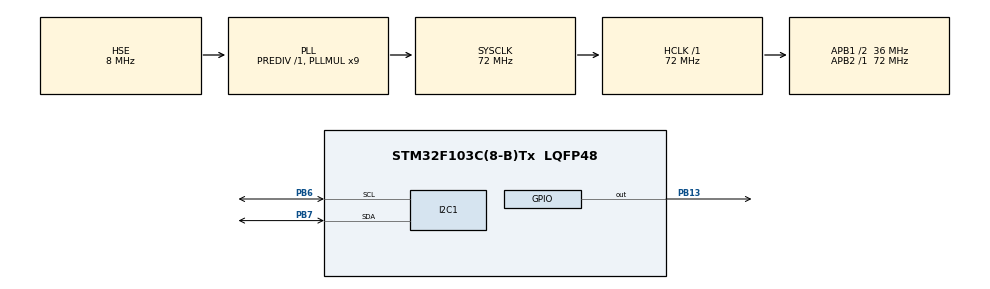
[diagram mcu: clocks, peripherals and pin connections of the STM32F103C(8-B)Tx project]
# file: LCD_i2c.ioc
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Mcu.Family=STM32F1
Mcu.Name=STM32F103C(8-B)Tx
Mcu.Package=LQFP48
NVIC.I2C1_ER_IRQn=true\:1\:0\:true\:false\:true\:true\:true\:true
NVIC.I2C1_EV_IRQn=true\:1\:0\:true\:false\:true\:true\:true\:true
NVIC.PriorityGroup=NVIC_PRIORITYGROUP_4
NVIC.TIM2_IRQn=true\:1\:0\:true\:false\:true\:true\:true\:true
PA13.Mode=Serial_Wire
PA13.Signal=SYS_JTMS-SWDIO
PA14.Mode=Serial_Wire
PA14.Signal=SYS_JTCK-SWCLK
PB13.Signal=GPIO_Output
PB6.Mode=I2C
PB6.Signal=I2C1_SCL
PB7.Mode=I2C
PB7.Signal=I2C1_SDA
PD0-OSC_IN.Mode=HSE-External-Oscillator
PD0-OSC_IN.Signal=RCC_OSC_IN
PD1-OSC_OUT.Mode=HSE-External-Oscillator
PD1-OSC_OUT.Signal=RCC_OSC_OUT
ProjectManager.HeapSize=0x200
ProjectManager.StackSize=0x400
ProjectManager.TargetToolchain=STM32CubeIDE
RCC.AHBFreq_Value=72000000
RCC.APB1CLKDivider=RCC_HCLK_DIV2
RCC.APB1Freq_Value=36000000
RCC.APB1TimFreq_Value=72000000
RCC.APB2Freq_Value=72000000
RCC.APB2TimFreq_Value=72000000
RCC.HCLKFreq_Value=72000000
RCC.PLLMUL=RCC_PLL_MUL9
RCC.PLLSourceVirtual=RCC_PLLSOURCE_HSE
RCC.SYSCLKFreq_VALUE=72000000
RCC.SYSCLKSource=RCC_SYSCLKSOURCE_PLLCLK
RCC.USBFreq_Value=72000000
TIM2.Period=65534
TIM2.Prescaler=71
VP_TIM2_VS_ClockSourceINT.Mode=Internal
board=custom

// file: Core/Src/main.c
/* USER CODE BEGIN Header */
/**
  ******************************************************************************
  * @file           : main.c
  * @brief          : Main program body
  ******************************************************************************
  * @attention
  *
  * Copyright (c) 2023 STMicroelectronics.
  * All rights reserved.
  *
  * This software is licensed under terms that can be found in the LICENSE file
  * in the root directory of this software component.
  * If no LICENSE file comes with this software, it is provided AS-IS.
  *
  ******************************************************************************
  */
/* USER CODE END Header */
#include "main.h"

/* USER CODE BEGIN Includes */
#include "i2c-lcd.h"
#include "stdio.h"
/* USER CODE END Includes */

/* USER CODE BEGIN PD */
#define DHT11_GPIO_Port GPIOB
#define DHT11_Pin GPIO_PIN_13
/* USER CODE END PD */

I2C_HandleTypeDef hi2c1;

TIM_HandleTypeDef htim2;
float t=0,h=0;

void SystemClock_Config(void);
static void MX_GPIO_Init(void);
static void MX_I2C1_Init(void);
static void MX_TIM2_Init(void);

/* USER CODE BEGIN 0 */
// delay theo mirco giây
void delay_us(int us){
	 __HAL_TIM_SetCounter(&htim2, 0);
	 while (__HAL_TIM_GetCounter(&htim2) < us);
}

// delay theo mili giây
void delay_ms(int ms){
	for(int i =0; i < ms; i++){
			delay_us(1000);
	}
}
/*----------DHT11-----------*/
void DHT_SetPinOut()
{
	GPIO_InitTypeDef GPIO_InitStruct = {0};
	GPIO_InitStruct.Pin = DHT11_Pin;
  GPIO_InitStruct.Mode = GPIO_MODE_OUTPUT_PP;
  GPIO_InitStruct.Speed = GPIO_SPEED_FREQ_LOW;
  HAL_GPIO_Init(DHT11_GPIO_Port, &GPIO_InitStruct);
}
void DHT_SetPinIn()
{
	GPIO_InitTypeDef GPIO_InitStruct = {0};
	GPIO_InitStruct.Pin = DHT11_Pin;
  GPIO_InitStruct.Mode = GPIO_MODE_INPUT;
  GPIO_InitStruct.Pull = GPIO_NOPULL;
  HAL_GPIO_Init(DHT11_GPIO_Port, &GPIO_InitStruct);
}

void DHT_WritePin(uint8_t Value)
{
	HAL_GPIO_WritePin(DHT11_GPIO_Port, DHT11_Pin, Value);
}
static uint8_t DHT_ReadPin()
{
	uint8_t Value;
	Value =  HAL_GPIO_ReadPin(DHT11_GPIO_Port, DHT11_Pin);
	return Value;
}

uint8_t DHT_Start()
{
	uint8_t Response = 0;
	DHT_SetPinOut();
	DHT_WritePin(0);
	delay_us(18000);
	DHT_SetPinIn();
	//delay_us(50);
	while(DHT_ReadPin());
	Response = DHT_ReadPin();
//	if (!DHT_ReadPin())
//	{
//		delay_us(80);
//		if(DHT_ReadPin())
//		{
//			Response = 1;
//		}
//		else
//		{
//			Response = 0;
//		}
//	}
//	while(DHT_ReadPin());
	return Response;
}
uint8_t DHT_Read()
{
	uint8_t Value = 0;
	for(int i = 0; i<8; i++)
	{
		while(!DHT_ReadPin());
		delay_us(40);
		if(!DHT_ReadPin())
		{
			Value &= ~(1<<(7-i));
		}
		else Value |= 1<<(7-i);
		while(DHT_ReadPin());
	}
	return Value;
}

//************************** High Level Layer ********************************************************//

void DHT_ReadTempHum()
{
	uint8_t Respone = 0;
	uint8_t Temp1, RH1;
//	uint16_t Temp, Humi, SUM = 0;
	Respone = DHT_Start();
	if(Respone){
		RH1 = DHT_Read();
		//RH2 = DHT_Read();
		Temp1 = DHT_Read();
		//Temp2 = DHT_Read();
	//	SUM = DHT_Read();
	//	Temp = (Temp1<<8)|Temp2;
	//	Humi = (RH1<<8)|RH2;
		t = (float)(Temp1);
		h = (float)(RH1);
	}
	else{
		t=0;h=0;
	}
}

/* USER CODE END 0 */

int main(void)
{

  /* MCU Configuration--------------------------------------------------------*/

  /* Reset of all peripherals, Initializes the Flash interface and the Systick. */
  HAL_Init();

  /* Configure the system clock */
  SystemClock_Config();

  /* Initialize all configured peripherals */
  MX_GPIO_Init();
  MX_I2C1_Init();
  MX_TIM2_Init();
  /* USER CODE BEGIN 2 */
  HAL_TIM_Base_Start(&htim2);

  lcd_init();

 // lcd_clear_display ();      //clear display lcd
  lcd_goto_XY (1,0); //set proper location on screen

  //lcd_send_cmd (char cmd);  // send command to the lcd

   //lcd_send_data ('Q');  // send data to the lcd

   lcd_send_string ("Hello world");  // send string to the lcd
   HAL_Delay(50);
   lcd_goto_XY (2,0);
   lcd_send_string ("Minh Tam");
   HAL_Delay(50);

  /* USER CODE END 2 */

  /* Infinite loop */
  while (1)
  {
	  DHT_ReadTempHum();
	  HAL_Delay(1000);
//lcd_goto_XY (1,0);
//	   lcd_send_string ("Hello world");  // send string to the lcd
//	   lcd_goto_XY (2,0);
//	   lcd_send_string ("Minh Tam");
  }
}

void SystemClock_Config(void)
{
  RCC_OscInitTypeDef RCC_OscInitStruct = {0};
  RCC_ClkInitTypeDef RCC_ClkInitStruct = {0};

  /** Initializes the RCC Oscillators according to the specified parameters
  * in the RCC_OscInitTypeDef structure.
  */
  RCC_OscInitStruct.OscillatorType = RCC_OSCILLATORTYPE_HSE;
  RCC_OscInitStruct.HSEState = RCC_HSE_ON;
  RCC_OscInitStruct.HSEPredivValue = RCC_HSE_PREDIV_DIV1;
  RCC_OscInitStruct.HSIState = RCC_HSI_ON;
  RCC_OscInitStruct.PLL.PLLState = RCC_PLL_ON;
  RCC_OscInitStruct.PLL.PLLSource = RCC_PLLSOURCE_HSE;
  RCC_OscInitStruct.PLL.PLLMUL = RCC_PLL_MUL9;
  if (HAL_RCC_OscConfig(&RCC_OscInitStruct) != HAL_OK)
  {
    Error_Handler();
  }

  /** Initializes the CPU, AHB and APB buses clocks
  */
  RCC_ClkInitStruct.ClockType = RCC_CLOCKTYPE_HCLK|RCC_CLOCKTYPE_SYSCLK
                              |RCC_CLOCKTYPE_PCLK1|RCC_CLOCKTYPE_PCLK2;
  RCC_ClkInitStruct.SYSCLKSource = RCC_SYSCLKSOURCE_PLLCLK;
  RCC_ClkInitStruct.AHBCLKDivider = RCC_SYSCLK_DIV1;
  RCC_ClkInitStruct.APB1CLKDivider = RCC_HCLK_DIV2;
  RCC_ClkInitStruct.APB2CLKDivider = RCC_HCLK_DIV1;

  if (HAL_RCC_ClockConfig(&RCC_ClkInitStruct, FLASH_LATENCY_2) != HAL_OK)
  {
    Error_Handler();
  }
}

static void MX_I2C1_Init(void)
{

  hi2c1.Instance = I2C1;
  hi2c1.Init.ClockSpeed = 100000;
  hi2c1.Init.DutyCycle = I2C_DUTYCYCLE_2;
  hi2c1.Init.OwnAddress1 = 0;
  hi2c1.Init.AddressingMode = I2C_ADDRESSINGMODE_7BIT;
  hi2c1.Init.DualAddressMode = I2C_DUALADDRESS_DISABLE;
  hi2c1.Init.OwnAddress2 = 0;
  hi2c1.Init.GeneralCallMode = I2C_GENERALCALL_DISABLE;
  hi2c1.Init.NoStretchMode = I2C_NOSTRETCH_DISABLE;
  if (HAL_I2C_Init(&hi2c1) != HAL_OK)
  {
    Error_Handler();
  }

}

static void MX_TIM2_Init(void)
{

  TIM_ClockConfigTypeDef sClockSourceConfig = {0};
  TIM_MasterConfigTypeDef sMasterConfig = {0};

  htim2.Instance = TIM2;
  htim2.Init.Prescaler = 71;
  htim2.Init.CounterMode = TIM_COUNTERMODE_UP;
  htim2.Init.Period = 65534;
  htim2.Init.ClockDivision = TIM_CLOCKDIVISION_DIV1;
  htim2.Init.AutoReloadPreload = TIM_AUTORELOAD_PRELOAD_DISABLE;
  if (HAL_TIM_Base_Init(&htim2) != HAL_OK)
  {
    Error_Handler();
  }
  sClockSourceConfig.ClockSource = TIM_CLOCKSOURCE_INTERNAL;
  if (HAL_TIM_ConfigClockSource(&htim2, &sClockSourceConfig) != HAL_OK)
  {
    Error_Handler();
  }
  sMasterConfig.MasterOutputTrigger = TIM_TRGO_RESET;
  sMasterConfig.MasterSlaveMode = TIM_MASTERSLAVEMODE_DISABLE;
  if (HAL_TIMEx_MasterConfigSynchronization(&htim2, &sMasterConfig) != HAL_OK)
  {
    Error_Handler();
  }

}

static void MX_GPIO_Init(void)
{
  GPIO_InitTypeDef GPIO_InitStruct = {0};

  /* GPIO Ports Clock Enable */
  __HAL_RCC_GPIOD_CLK_ENABLE();
  __HAL_RCC_GPIOB_CLK_ENABLE();
  __HAL_RCC_GPIOA_CLK_ENABLE();

  /*Configure GPIO pin Output Level */
  HAL_GPIO_WritePin(GPIOB, GPIO_PIN_13, GPIO_PIN_RESET);

  /*Configure GPIO pin : PB13 */
  GPIO_InitStruct.Pin = GPIO_PIN_13;
  GPIO_InitStruct.Mode = GPIO_MODE_OUTPUT_PP;
  GPIO_InitStruct.Pull = GPIO_NOPULL;
  GPIO_InitStruct.Speed = GPIO_SPEED_FREQ_LOW;
  HAL_GPIO_Init(GPIOB, &GPIO_InitStruct);

}

void Error_Handler(void)
{
  __disable_irq();
  while (1)
  {
  }
}
